# SAM9X60D1G_SOM device description
Architecture: ARM926EJ-S; Family: SAM9; Series: SAM9X6
Registers are 32-bit, read-write, no defined reset value unless marked. A register's access mark holds for its fields unless they carry their own. Offsets are from the block's base; [hi:lo] are bit positions.

## SHDWC — Shutdown Controller
Instances: SHDWC 0xFFFFFE10
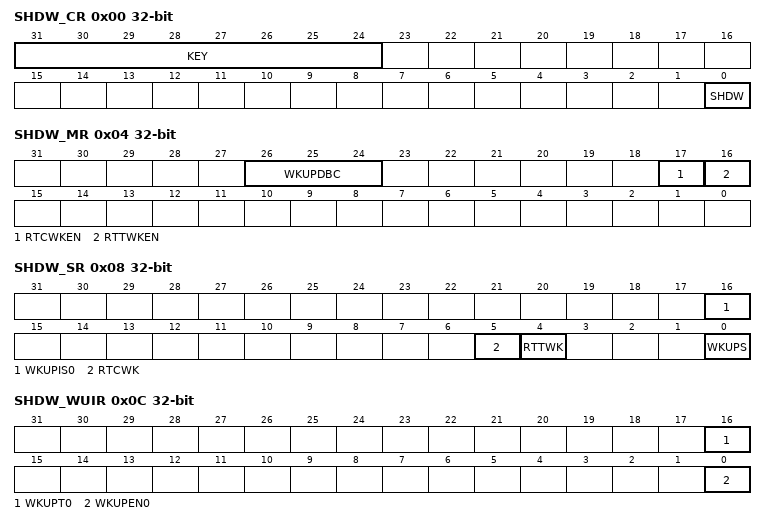
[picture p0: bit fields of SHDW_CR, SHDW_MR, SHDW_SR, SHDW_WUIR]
0x00 SHDW_CR wo — Control Register
  [31:24] KEY — Password
    165=PASSWD (Writing any other value in this field aborts the write operation.)
  [0] SHDW — Shutdown Command
0x04 SHDW_MR — Mode Register
  [26:24] WKUPDBC — Wakeup Inputs Debouncer Period
    0=IMMEDIATE (Immediate, no debouncing, detected active at least on one MD_SLCK edge.); 1=_3_SLCK (WKUP shall be in its active state for at least 3 MD_SLCK periods); 2=_32_SLCK (WKUP shall be in its active state for at least 32 MD_SLCK periods); 3=_512_SLCK (WKUP shall be in its active state for at least 512 MD_SLCK periods); 4=_4096_SLCK (WKUP shall be in its active state for at least 4,096 MD_SLCK periods); 5=_32768_SLCK (WKUP shall be in its active state for at least 32,768 MD_SLCK periods)
  [17] RTCWKEN — Real-time Clock Wakeup Enable
  [16] RTTWKEN — Real-time Timer Wakeup Enable
0x08 SHDW_SR ro — Status Register
  [16] WKUPIS0 — Wakeup 0 Input Status
    0=DISABLE (The wakeup 0 input is disabled, or was inactive at the time the debouncer triggered a wakeup event.); 1=ENABLE (The wakeup 0 input was active at the time the debouncer triggered a wakeup event.)
  [5] RTCWK — Real-time Clock Wakeup
  [4] RTTWK — Real-time Timer Wakeup
  [0] WKUPS — WKUP Wakeup Status
    0=NO (No wakeup due to the assertion of the WKUP pin has occurred since the last read of SHDW_SR.); 1=PRESENT (At least one wakeup due to the assertion of the WKUP pin has occurred since the last read of SHDW_SR.)
0x0C SHDW_WUIR — Wakeup Inputs Register
  [16] WKUPT0 — Wakeup 0 Input Type
    0=LOW (A falling edge followed by a low level on the wakeup 0 input, for a period defined by WKUPDBC, forces wakeup of the core power supply.); 1=HIGH (A rising edge followed by a high level on the wakeup 0 input, for a period defined by WKUPDBC, forces wakeup of the core power supply.)
  [0] WKUPEN0 — Wakeup 0 Input Enable
    0=DISABLE (The wakeup 0 input has no wakeup effect.); 1=ENABLE (The wakeup 0 input forces wakeup of the core power supply.)

## SYSCWP — External Interrupt Controller
Instances: SYSCWP 0xFFFFFEDC
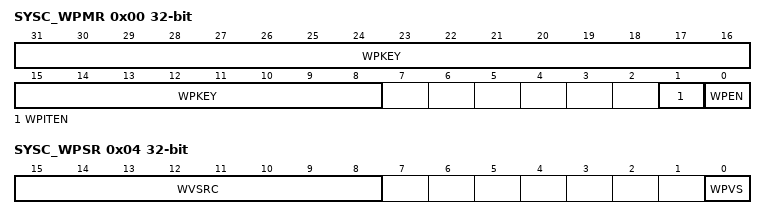
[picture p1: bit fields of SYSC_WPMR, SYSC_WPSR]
0x00 SYSC_WPMR — Write Protection Mode Register
  [31:8] WPKEY — Write Protection Key
    0x535943=PASSWD (Writing any other value in this field aborts the write operation of the WPEN and WPITEN bits. Always reads as 0.)
  [1] WPITEN — Write Protection RTC Interrupt Enable
  [0] WPEN — Write Protection Enable
0x04 SYSC_WPSR ro — Write Protection Status Register
  [15:8] WVSRC — Write Violation Source
  [0] WPVS — Write Protection Register Violation Status

## TRNG — True Random Number Generator
Instances: TRNG 0xF0030000
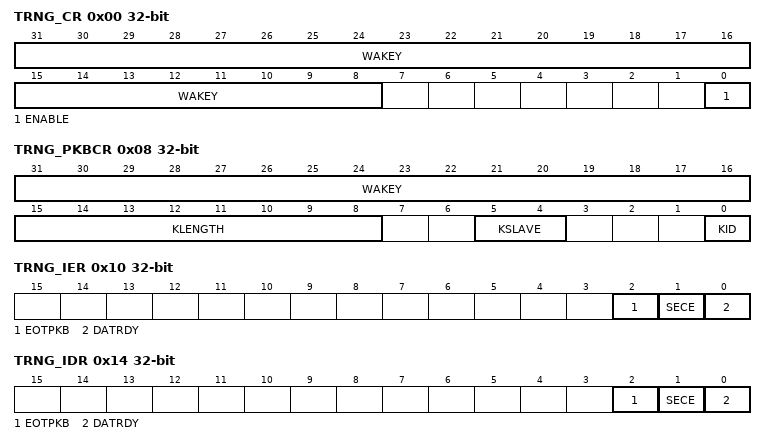
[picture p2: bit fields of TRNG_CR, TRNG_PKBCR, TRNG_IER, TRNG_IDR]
0x00 TRNG_CR wo — Control Register
  [31:8] WAKEY — Register Write Access Key
    0x524E47=PASSWD (Writing any other value in this field aborts the write operation.)
  [0] ENABLE — Enable TRNG to Provide Random Values
0x04 TRNG_MR — Mode Register
  [0] HALFR — Half Rate Enable
0x08 TRNG_PKBCR wo — Private Key Bus Control Register
  [31:16] WAKEY — Register Write Access Key
    0x524B=PASSWD (Writing any other value in this field aborts the write operation.)
  [15:8] KLENGTH — Key Length
  [5:4] KSLAVE — Key Bus Slave
    0=TDES_ID (Selects the TDES.); 1=AES_ID (Selects the AES.); 2=OTPC_ID (Selects the OTPC.)
  [0] KID — Key ID (Must be Always Written to 0)
0x10 TRNG_IER wo — Interrupt Enable Register
  [2] EOTPKB — End Of Transfer on Private Key Bus Interrupt Enable
  [1] SECE — Security and/or Safety Event Interrupt Enable
  [0] DATRDY — Data Ready Interrupt Enable
0x14 TRNG_IDR wo — Interrupt Disable Register
  [2] EOTPKB — End Of Transfer on Private Key Bus Interrupt Disable
  [1] SECE — Security and/or Safety Event Interrupt Disable
  [0] DATRDY — Data Ready Interrupt Disable
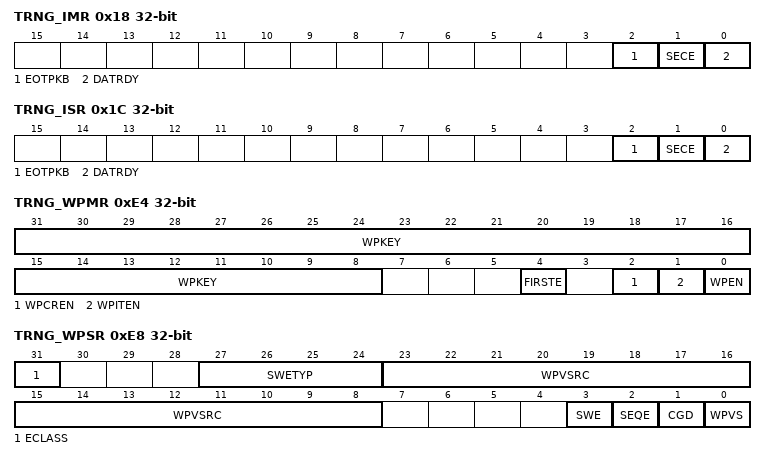
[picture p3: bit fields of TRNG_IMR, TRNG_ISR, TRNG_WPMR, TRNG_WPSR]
0x18 TRNG_IMR ro — Interrupt Mask Register
  [2] EOTPKB — End Of Transfer on Private Key Bus Interrupt Mask
  [1] SECE — Security and/or Safety Event Interrupt Mask
  [0] DATRDY — Data Ready Interrupt Mask
0x1C TRNG_ISR ro — Interrupt Status Register
  [2] EOTPKB — End Of Transfer on Private Key Bus (cleared on read)
  [1] SECE — Security and/or Safety Event (cleared on read)
  [0] DATRDY — Data Ready (cleared on read)
0x50 TRNG_ODATA ro — Output Data Register
  [31:0] ODATA — Output Data
0xE4 TRNG_WPMR — Write Protection Mode Register
  [31:8] WPKEY — Write Protection Key
    0x524E47=PASSWD (Writing any other value in this field aborts the write operation of bits WPEN, WPITEN and WPCREN. Always reads as 0.)
  [4] FIRSTE — First Error Report Enable
  [2] WPCREN — Write Protection Control Enable
  [1] WPITEN — Write Protection Interrupt Enable
  [0] WPEN — Write Protection Enable
0xE8 TRNG_WPSR ro — Write Protection Status Register
  [31] ECLASS — Software Error Class (cleared on read)
    0=WARNING (An abnormal access that does not affect system functionality.); 1=ERROR (Reading TRNG_ODATA when TRNG was disabled or TRNG used for private key bus transfer. TRNG does not provide a random value. Writing to the PKB_CTRL register while a private key bus transfer is ongoing does not launch a new private key bus transfer.)
  [27:24] SWETYP — Software Error Type (cleared on read)
    0=READ_WO (TRNG is enabled and a write-only register has been read (Warning).); 1=WRITE_RO (TRNG is enabled and a write access has been performed on a read-only register (Warning).); 2=UNDEF_RW (Access to an undefined address.); 3=TRNG_DIS (The TRNG_ODATA register was read when TRNG was disabled or TRNG used for private key bus transfer (Error).); 4=PKB_BUSY (A write access to the PKB_CTRL register has been attempted during a private key bus transfer (Error).)
  [23:8] WPVSRC — Write Protection Violation Source (cleared on read)
  [3] SWE — Software Control Error (cleared on read)
  [2] SEQE — Internal Sequencer Error (cleared on read)
  [1] CGD — Clock Glitch Detected (cleared on read)
  [0] WPVS — Write Protection Violation Status (cleared on read)

## WDT — Watchdog Timer
Instances: WDT 0xFFFFFF80
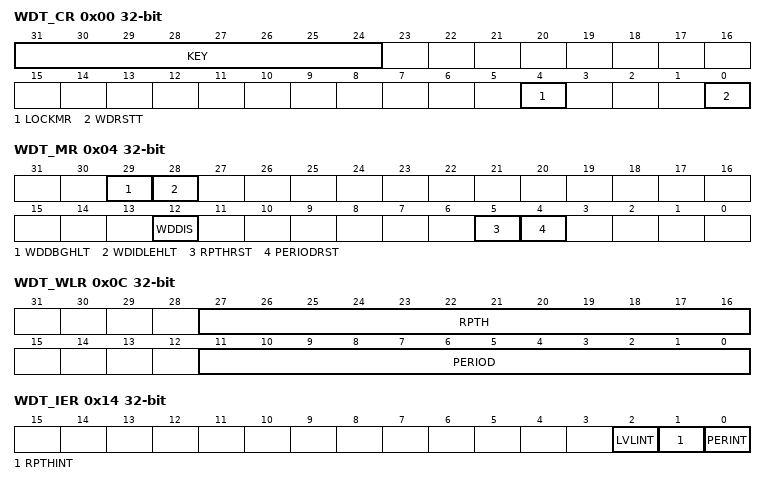
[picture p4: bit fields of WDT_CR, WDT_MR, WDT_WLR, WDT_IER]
0x00 WDT_CR wo — Control Register
  [31:24] KEY — Password
    165=PASSWD (Writing any other value in this field aborts the write operation.)
  [4] LOCKMR — Lock Mode Register Write Access
  [0] WDRSTT — Watchdog Restart
0x04 WDT_MR — Mode Register
  [29] WDDBGHLT — Watchdog Debug Halt
  [28] WDIDLEHLT — Watchdog Idle Halt
  [12] WDDIS — Watchdog Disable
  [5] RPTHRST — Minimum Restart Period
  [4] PERIODRST — Period Reset
0x08 WDT_VR ro — Value Register
  [11:0] COUNTER — Watchdog Down Counter Value
0x0C WDT_WLR — Window Level Register
  [27:16] RPTH — Repeat Threshold
  [11:0] PERIOD — Watchdog Period
0x10 WDT_ILR — Interrupt Level Register
  [11:0] LVLTH — Level Threshold
0x14 WDT_IER wo — Interrupt Enable Register
  [2] LVLINT — Interrupt Level Threshold Interrupt Enable
  [1] RPTHINT — Repeat Threshold Interrupt Enable
  [0] PERINT — Period Interrupt Enable
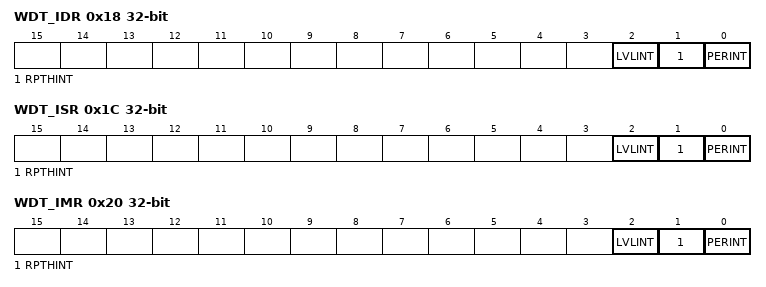
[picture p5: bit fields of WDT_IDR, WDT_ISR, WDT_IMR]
0x18 WDT_IDR wo — Interrupt Disable Register
  [2] LVLINT — Interrupt Level Threshold Interrupt Disable
  [1] RPTHINT — Repeat Threshold Interrupt Disable
  [0] PERINT — Period Interrupt Disable
0x1C WDT_ISR ro — Interrupt Status Register
  [2] LVLINT — Interrupt Level Threshold Interrupt Status (cleared on read)
  [1] RPTHINT — Repeat Threshold Interrupt Status (cleared on read)
  [0] PERINT — Period Interrupt Status (cleared on read)
0x20 WDT_IMR ro — Interrupt Mask Register
  [2] LVLINT — Interrupt Level Threshold Interrupt Mask
  [1] RPTHINT — Repeat Threshold Interrupt Mask
  [0] PERINT — Period Interrupt Mask

## XDMAC_DSC3 — XDMAC Descriptor View 3
0x00 XDMAC_DSC3_MBR_NDA reset 0x0 — Next Descriptor Address Member
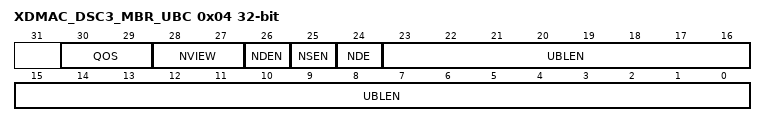
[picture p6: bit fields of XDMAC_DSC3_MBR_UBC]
0x04 XDMAC_DSC3_MBR_UBC ro — Descriptor Structure Microblock Control Member
  [30:29] QOS — Channel Quality of Service Level
  [28:27] NVIEW — Next Descriptor View
  [26] NDEN — Next Descriptor Destination Update
  [25] NSEN — Next Descriptor Source Update
  [24] NDE — Next Descriptor Enable
  [23:0] UBLEN — Microblock Length
0x08 XDMAC_DSC3_MBR_SA reset 0x0 — Source Address Member
0x0C XDMAC_DSC3_MBR_DA reset 0x0 — Destination Address Member
0x10 XDMAC_DSC3_MBR_CFG reset 0x0 — Configuration Register
0x14 XDMAC_DSC3_MBR_BC reset 0x0 — Block Control Member
0x18 XDMAC_DSC3_MBR_DS reset 0x0 — Data Stride Member
0x1C XDMAC_DSC3_MBR_SUS reset 0x0 — Source Microblock Stride Member
0x20 XDMAC_DSC3_MBR_DUS reset 0x0 — Destination Microblock Stride Member

## XDMAC_DSC2 — XDMAC Descriptor View 2
Registers as XDMAC_DSC3 (with XDMAC_DSC3 read as XDMAC_DSC2), without XDMAC_DSC3_MBR_BC, XDMAC_DSC3_MBR_DS, XDMAC_DSC3_MBR_SUS, XDMAC_DSC3_MBR_DUS.

## XDMAC_DSC1 — XDMAC Descriptor View 1
Registers as XDMAC_DSC3 (with XDMAC_DSC3 read as XDMAC_DSC1), without XDMAC_DSC3_MBR_CFG, XDMAC_DSC3_MBR_BC, XDMAC_DSC3_MBR_DS, XDMAC_DSC3_MBR_SUS, XDMAC_DSC3_MBR_DUS.

## XDMAC_DSC0 — XDMAC Descriptor View 0
Registers as XDMAC_DSC3 (with XDMAC_DSC3 read as XDMAC_DSC0), without XDMAC_DSC3_MBR_SA, XDMAC_DSC3_MBR_DA, XDMAC_DSC3_MBR_CFG, XDMAC_DSC3_MBR_BC, XDMAC_DSC3_MBR_DS, XDMAC_DSC3_MBR_SUS, XDMAC_DSC3_MBR_DUS; these are added or differ:
0x08 XDMAC_DSC0_MBR_TA reset 0x0 — Transfer Address Member
